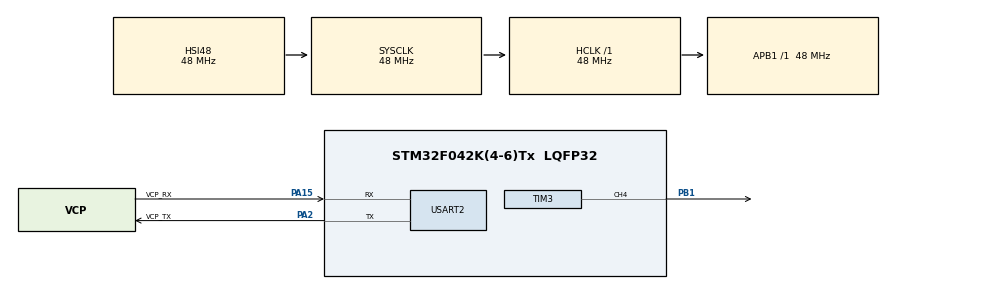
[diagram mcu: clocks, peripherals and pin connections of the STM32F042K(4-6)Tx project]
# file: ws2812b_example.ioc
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Dma.Request0=TIM3_CH4/UP
Dma.TIM3_CH4/UP.0.Direction=DMA_MEMORY_TO_PERIPH
Dma.TIM3_CH4/UP.0.Instance=DMA1_Channel3
Dma.TIM3_CH4/UP.0.MemDataAlignment=DMA_MDATAALIGN_BYTE
Dma.TIM3_CH4/UP.0.MemInc=DMA_MINC_ENABLE
Dma.TIM3_CH4/UP.0.Mode=DMA_CIRCULAR
Dma.TIM3_CH4/UP.0.PeriphDataAlignment=DMA_PDATAALIGN_HALFWORD
Dma.TIM3_CH4/UP.0.PeriphInc=DMA_PINC_DISABLE
Dma.TIM3_CH4/UP.0.Priority=DMA_PRIORITY_LOW
Mcu.Family=STM32F0
Mcu.Name=STM32F042K(4-6)Tx
Mcu.Package=LQFP32
NVIC.DMA1_Channel2_3_IRQn=true\:0\:0\:false\:false\:true\:false\:true
PA13.GPIO_Label=SWDIO
PA13.Mode=Serial_Wire
PA13.Signal=SYS_SWDIO
PA14.GPIO_Label=SWCLK
PA14.Mode=Serial_Wire
PA14.Signal=SYS_SWCLK
PA15.GPIO_Label=VCP_RX
PA15.Mode=Asynchronous
PA15.Signal=USART2_RX
PA2.GPIO_Label=VCP_TX
PA2.Mode=Asynchronous
PA2.Signal=USART2_TX
PB1.Signal=S_TIM3_CH4
ProjectManager.HeapSize=0x200
ProjectManager.StackSize=0x400
ProjectManager.TargetToolchain=STM32CubeIDE
RCC.AHBFreq_Value=48000000
RCC.APB1Freq_Value=48000000
RCC.APB1TimFreq_Value=48000000
RCC.HCLKFreq_Value=48000000
RCC.PLLMUL=RCC_PLL_MUL6
RCC.SYSCLKFreq_VALUE=48000000
RCC.SYSCLKSource=RCC_SYSCLKSOURCE_HSI48
SH.S_TIM3_CH4.0=TIM3_CH4,PWM Generation4 CH4
TIM3.Channel-PWM\ Generation4\ CH4=TIM_CHANNEL_4
TIM3.Period=60
USART2.VirtualMode-Asynchronous=VM_ASYNC
board=NUCLEO-F042K6

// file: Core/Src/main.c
/* USER CODE BEGIN Header */
/**
  ******************************************************************************
  * @file           : main.c
  * @brief          : Main program body
  ******************************************************************************
  * @attention
  *
  * <h2><center>&copy; Copyright (c) 2021 STMicroelectronics.
  * All rights reserved.</center></h2>
  *
  * This software component is licensed by ST under BSD 3-Clause license,
  * the "License"; You may not use this file except in compliance with the
  * License. You may obtain a copy of the License at:
  *                        opensource.org/licenses/BSD-3-Clause
  *
  ******************************************************************************
  */
/* USER CODE END Header */
#include "main.h"
#include "dma.h"
#include "tim.h"
#include "usart.h"
#include "gpio.h"

/* USER CODE BEGIN Includes */
#include "ws2812b_base.h"
#include "test.h"
/* USER CODE END Includes */

void SystemClock_Config(void);

int main(void)
{

  /* MCU Configuration--------------------------------------------------------*/

  /* Reset of all peripherals, Initializes the Flash interface and the Systick. */
  HAL_Init();

  /* Configure the system clock */
  SystemClock_Config();

  /* Initialize all configured peripherals */
  MX_GPIO_Init();
  MX_USART2_UART_Init();
  MX_DMA_Init();
  MX_TIM3_Init();
  /* USER CODE BEGIN 2 */
  ws2812b_init();

  /* USER CODE END 2 */

  /* Infinite loop */
  /* USER CODE BEGIN WHILE */
  while (1)
  {
	  ws2812b_main();
	  test_main();
    /* USER CODE END WHILE */

  }
}

void SystemClock_Config(void)
{
  RCC_OscInitTypeDef RCC_OscInitStruct = {0};
  RCC_ClkInitTypeDef RCC_ClkInitStruct = {0};

  /** Initializes the RCC Oscillators according to the specified parameters
  * in the RCC_OscInitTypeDef structure.
  */
  RCC_OscInitStruct.OscillatorType = RCC_OSCILLATORTYPE_HSI48;
  RCC_OscInitStruct.HSI48State = RCC_HSI48_ON;
  RCC_OscInitStruct.PLL.PLLState = RCC_PLL_NONE;
  if (HAL_RCC_OscConfig(&RCC_OscInitStruct) != HAL_OK)
  {
    Error_Handler();
  }
  /** Initializes the CPU, AHB and APB buses clocks
  */
  RCC_ClkInitStruct.ClockType = RCC_CLOCKTYPE_HCLK|RCC_CLOCKTYPE_SYSCLK
                              |RCC_CLOCKTYPE_PCLK1;
  RCC_ClkInitStruct.SYSCLKSource = RCC_SYSCLKSOURCE_HSI48;
  RCC_ClkInitStruct.AHBCLKDivider = RCC_SYSCLK_DIV1;
  RCC_ClkInitStruct.APB1CLKDivider = RCC_HCLK_DIV1;

  if (HAL_RCC_ClockConfig(&RCC_ClkInitStruct, FLASH_LATENCY_1) != HAL_OK)
  {
    Error_Handler();
  }
}

void Error_Handler(void)
{
  __disable_irq();
  while (1)
  {
  }
}

/************************ (C) COPYRIGHT STMicroelectronics *****END OF FILE****/
